VERSION "created by canmatrix"

NS_ :

BS_:

BU_: ME_AWS_CANA
VAL_TABLE_ CurDivValid 0 "Invalid" 1 "Description for the value '0x1'" ;
VAL_TABLE_ Lane_Type 0 "Dashed" 1 "Solid" 2 "undecided" 3 "Road Edge" 4 "Double Lane" 5 "Bott's Dots" 6 "invalid" ;
VAL_TABLE_ Model_Degree 0 "Parabolic model" 1 "Linear model" 2 "3rd-degree model" ;
VAL_TABLE_ Quality 0 "Low quality" 1 "Low quality" 2 "High quality" 3 "High quality" ;
VAL_TABLE_ Ref_Point_1_Validity 0 "Invalid" 1 "Valid" ;
VAL_TABLE_ Ref_Point_2_Validity 0 "Invalid" 1 "Valid" ;
VAL_TABLE_ Validity 0 "Invalid" 1 "Valid" ;
VAL_TABLE_ View_Ragne_Availability 0 "Not Valid" 1 "Valid" ;

BO_ 3221225472 VECTOR__INDEPENDENT_SIG_MSG: 0 Vector__XXX
 SG_ Shield_Configuration : 0|8@1+ (1,0) [0|0] "" Vector__XXX
 SG_ reserved : 0|32@1- (1,0) [0|255] "" Vector__XXX
 SG_ reserved3 : 0|3@1- (1,0) [0|3] "" Vector__XXX
 SG_ reserved2 : 0|2@1- (1,0) [0|1] "" Vector__XXX
 SG_ reserved1 : 0|2@1- (1,0) [0|1] "" Vector__XXX
 SG_ HighBeam : 0|1@1- (1,0) [0|1] "" Vector__XXX
 SG_ LowBeam : 0|1@1- (1,0) [0|1] "" Vector__XXX
 SG_ wippers : 0|1@1- (1,0) [0|1] "" Vector__XXX
 SG_ right_blink : 0|1@1- (1,0) [0|1] "" Vector__XXX
 SG_ Left_blink : 0|1@1- (1,0) [0|1] "" Vector__XXX
 SG_ Brakes : 0|1@1- (1,0) [0|1] "" Vector__XXX
 SG_ LowBeam_availabled : 0|1@1- (1,0) [0|1] "" Vector__XXX
 SG_ HighBeam_availabled : 0|1@1- (1,0) [0|1] "" Vector__XXX
 SG_ Wipers_availabled : 0|1@1- (1,0) [0|1] "" Vector__XXX
 SG_ View_Range_Availability : 0|1@1+ (1,0) [0|0] "" Vector__XXX
 SG_ View_Range : 0|15@1+ (0.00390625,0) [0|127.99609375] "meter" Vector__XXX
 SG_ Heading_Angle : 0|16@1+ (0.0009765625,-31.9990234375) [-0.357|0.357] "radians" Vector__XXX
 SG_ Reserved_10 : 0|3@1+ (1,0) [0|0] "" Vector__XXX
 SG_ Protocol_Version : 0|8@1+ (1,0) [0|255] "" Vector__XXX
 SG_ Active_Version_Number_Section : 0|2@1+ (1,0) [0|3] "" Vector__XXX
 SG_ Application_Version : 0|8@1+ (1,0) [0|255] "" Vector__XXX
 SG_ reserved5 : 0|5@1- (1,0) [0|23] "" Vector__XXX
 SG_ reserved4 : 0|5@1- (1,0) [0|4] "" Vector__XXX
 SG_ reserved20 : 0|2@1- (1,0) [0|0] "" Vector__XXX
 SG_ reserved21 : 0|1@1- (1,0) [0|0] "" Vector__XXX
 SG_ reserved0 : 0|5@1- (1,0) [0|0] "" Vector__XXX
 SG_ reserved1 : 0|3@1- (1,0) [0|0] "" Vector__XXX
 SG_ TSR_enabbled : 0|1@1+ (1,0) [0|1] "" Vector__XXX
 SG_ Rainy_HW_enabled : 0|1@1+ (1,0) [0|1] "" Vector__XXX
 SG_ Rain_HW : 0|1@1+ (1,0) [0|1] "" Vector__XXX
 SG_ HW_repeatable_enabled : 0|1@1+ (1,0) [0|1] "" Vector__XXX
 SG_ Blinker_reminder_enabled : 0|1@1+ (1,0) [0|1] "" Vector__XXX
 SG_ RLDW_on : 0|1@1+ (1,0) [0|1] "" Vector__XXX
 SG_ LLDW_on : 0|1@1+ (1,0) [0|1] "" Vector__XXX
 SG_ Maintenance : 0|1@1+ (1,0) [0|1] "" Vector__XXX
 SG_ Error_code : 0|7@1+ (1,0) [0|127] "" Vector__XXX
 SG_ Error_Active : 0|1@1+ (1,0) [0|1] "" Vector__XXX
 SG_ FLA_Armed : 0|1@1+ (1,0) [0|1] "" Vector__XXX
 SG_ Hi_Low_BeamControl : 0|1@1+ (1,0) [0|1] "" Vector__XXX
 SG_ Zero_speed : 0|1@1+ (1,0) [0|1] "" Vector__XXX
 SG_ Sound_type : 0|3@1+ (1,0) [0|7] "" Vector__XXX

BO_ 1888 signal_car: 8 Vector__XXX
 SG_ speed : 16|8@1+ (1,0) [0|255] "km\h" Vector__XXX

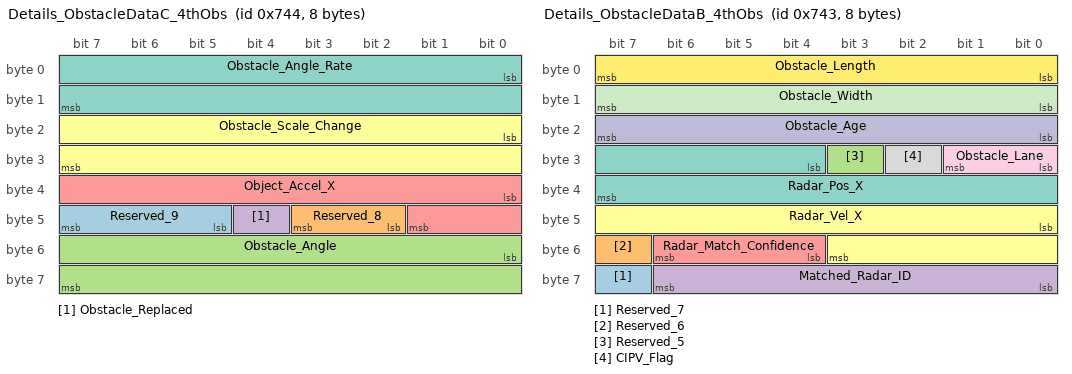
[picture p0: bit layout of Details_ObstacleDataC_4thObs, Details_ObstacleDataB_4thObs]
BO_ 1860 Details_ObstacleDataC_4thObs: 8 Vector__XXX
 SG_ Reserved_9 : 45|3@1+ (1,0) [0|0] "" Vector__XXX
 SG_ Reserved_8 : 42|2@1+ (1,0) [0|0] "" Vector__XXX
 SG_ Obstacle_Angle : 48|16@1- (0.01,0) [-327.68|327.67] "degree" Vector__XXX
 SG_ Obstacle_Replaced : 44|1@1+ (1,0) [0|0] "" Vector__XXX
 SG_ Object_Accel_X : 32|10@1- (0.03,0) [-15.36|15.33] "M/S2" Vector__XXX
 SG_ Obstacle_Scale_Change : 16|16@1- (0.0002,0) [-6.5536|6.5534] "pix/sec" Vector__XXX
 SG_ Obstacle_Angle_Rate : 0|16@1- (0.01,0) [-327.68|327.67] "degree" Vector__XXX

BO_ 1859 Details_ObstacleDataB_4thObs: 8 Vector__XXX
 SG_ Reserved_7 : 63|1@1+ (1,0) [0|0] "" Vector__XXX
 SG_ Reserved_6 : 55|1@1- (1,0) [0|0] "" Vector__XXX
 SG_ Reserved_5 : 27|1@1+ (1,0) [0|0] "" Vector__XXX
 SG_ Matched_Radar_ID : 56|7@1+ (1,0) [0|127] "" Vector__XXX
 SG_ Radar_Match_Confidence : 52|3@1+ (1,0) [0|7] "" Vector__XXX
 SG_ Radar_Vel_X : 40|12@1- (0.0625,0) [-128|127.9375] "meters/sec" Vector__XXX
 SG_ Radar_Pos_X : 28|12@1+ (0.0625,0) [0|255.9375] "meters" Vector__XXX
 SG_ CIPV_Flag : 26|1@1+ (1,0) [0|0] "" Vector__XXX
 SG_ Obstacle_Lane : 24|2@1+ (1,0) [0|3] "" Vector__XXX
 SG_ Obstacle_Age : 16|8@1+ (1,0) [0|255] "" Vector__XXX
 SG_ Obstacle_Width : 8|8@1+ (0.05,0) [0|12.75] "m" Vector__XXX
 SG_ Obstacle_Length : 0|8@1+ (0.5,0) [0|31] "m" Vector__XXX

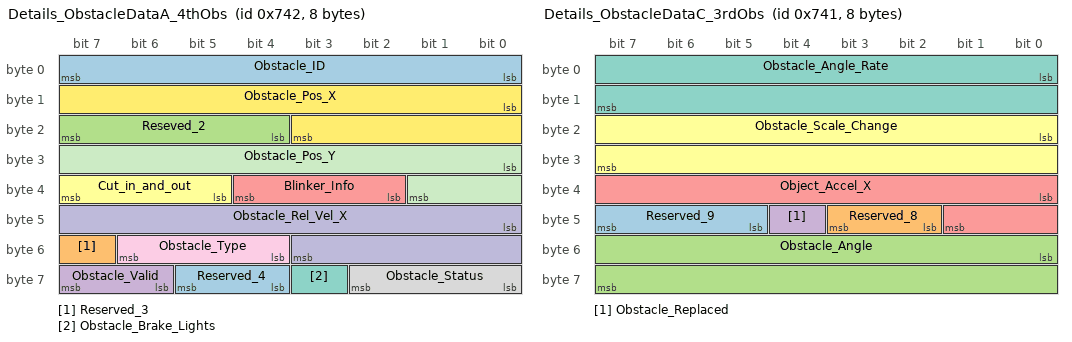
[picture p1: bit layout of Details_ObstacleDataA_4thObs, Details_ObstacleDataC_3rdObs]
BO_ 1858 Details_ObstacleDataA_4thObs: 8 Vector__XXX
 SG_ Reserved_4 : 60|2@1- (1,0) [0|0] "" Vector__XXX
 SG_ Reserved_3 : 55|1@1+ (1,0) [0|0] "" Vector__XXX
 SG_ Reseved_2 : 20|4@1+ (1,0) [0|0] "" Vector__XXX
 SG_ Obstacle_Valid : 62|2@1+ (1,0) [0|3] "" Vector__XXX
 SG_ Blinker_Info : 34|3@1+ (1,0) [0|7] "" Vector__XXX
 SG_ Cut_in_and_out : 37|3@1+ (1,0) [0|7] "" Vector__XXX
 SG_ Obstacle_Brake_Lights : 59|1@1- (1,0) [0|0] "" Vector__XXX
 SG_ Obstacle_Status : 56|3@1+ (1,0) [0|7] "" Vector__XXX
 SG_ Obstacle_Type : 52|3@1+ (1,0) [0|7] "" Vector__XXX
 SG_ Obstacle_Rel_Vel_X : 40|12@1- (0.0625,0) [-128|127.9375] "meters/sec" Vector__XXX
 SG_ Obstacle_Pos_Y : 24|10@1- (0.0625,0) [-32|31.9375] "meters" Vector__XXX
 SG_ Obstacle_Pos_X : 8|12@1+ (0.0625,0) [0|255.9375] "meters" Vector__XXX
 SG_ Obstacle_ID : 0|8@1+ (1,0) [0|63] "" Vector__XXX

BO_ 1857 Details_ObstacleDataC_3rdObs: 8 Vector__XXX
 SG_ Reserved_9 : 45|3@1+ (1,0) [0|0] "" Vector__XXX
 SG_ Reserved_8 : 42|2@1+ (1,0) [0|0] "" Vector__XXX
 SG_ Obstacle_Angle : 48|16@1- (0.01,0) [-327.68|327.67] "degree" Vector__XXX
 SG_ Obstacle_Replaced : 44|1@1+ (1,0) [0|0] "" Vector__XXX
 SG_ Object_Accel_X : 32|10@1- (0.03,0) [-15.36|15.33] "M/S2" Vector__XXX
 SG_ Obstacle_Scale_Change : 16|16@1- (0.0002,0) [-6.5536|6.5534] "pix/sec" Vector__XXX
 SG_ Obstacle_Angle_Rate : 0|16@1- (0.01,0) [-327.68|327.67] "degree" Vector__XXX

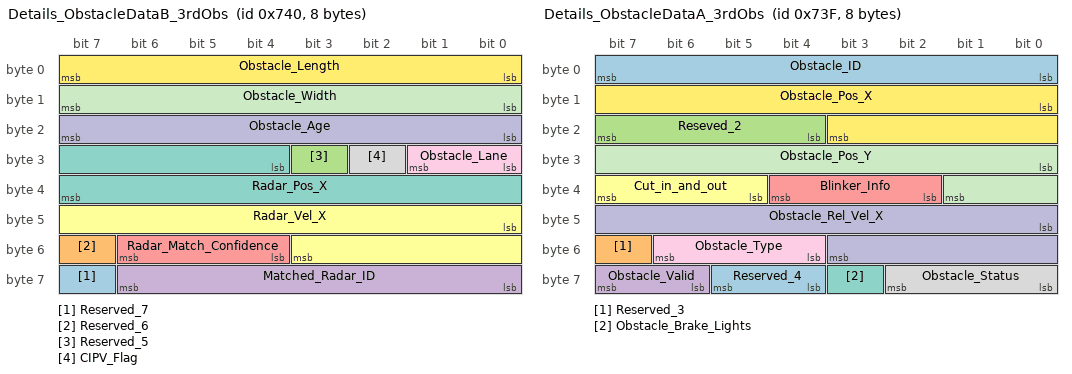
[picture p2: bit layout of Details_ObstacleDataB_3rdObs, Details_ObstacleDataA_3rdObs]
BO_ 1856 Details_ObstacleDataB_3rdObs: 8 Vector__XXX
 SG_ Reserved_7 : 63|1@1+ (1,0) [0|0] "" Vector__XXX
 SG_ Reserved_6 : 55|1@1- (1,0) [0|0] "" Vector__XXX
 SG_ Reserved_5 : 27|1@1+ (1,0) [0|0] "" Vector__XXX
 SG_ Matched_Radar_ID : 56|7@1+ (1,0) [0|127] "" Vector__XXX
 SG_ Radar_Match_Confidence : 52|3@1+ (1,0) [0|7] "" Vector__XXX
 SG_ Radar_Vel_X : 40|12@1- (0.0625,0) [-128|127.9375] "meters/sec" Vector__XXX
 SG_ Radar_Pos_X : 28|12@1+ (0.0625,0) [0|255.9375] "meters" Vector__XXX
 SG_ CIPV_Flag : 26|1@1+ (1,0) [0|0] "" Vector__XXX
 SG_ Obstacle_Lane : 24|2@1+ (1,0) [0|3] "" Vector__XXX
 SG_ Obstacle_Age : 16|8@1+ (1,0) [0|255] "" Vector__XXX
 SG_ Obstacle_Width : 8|8@1+ (0.05,0) [0|12.75] "m" Vector__XXX
 SG_ Obstacle_Length : 0|8@1+ (0.5,0) [0|31] "m" Vector__XXX

BO_ 1855 Details_ObstacleDataA_3rdObs: 8 Vector__XXX
 SG_ Reserved_4 : 60|2@1- (1,0) [0|0] "" Vector__XXX
 SG_ Reserved_3 : 55|1@1+ (1,0) [0|0] "" Vector__XXX
 SG_ Reseved_2 : 20|4@1+ (1,0) [0|0] "" Vector__XXX
 SG_ Obstacle_Valid : 62|2@1+ (1,0) [0|3] "" Vector__XXX
 SG_ Blinker_Info : 34|3@1+ (1,0) [0|7] "" Vector__XXX
 SG_ Cut_in_and_out : 37|3@1+ (1,0) [0|7] "" Vector__XXX
 SG_ Obstacle_Brake_Lights : 59|1@1- (1,0) [0|0] "" Vector__XXX
 SG_ Obstacle_Status : 56|3@1+ (1,0) [0|7] "" Vector__XXX
 SG_ Obstacle_Type : 52|3@1+ (1,0) [0|7] "" Vector__XXX
 SG_ Obstacle_Rel_Vel_X : 40|12@1- (0.0625,0) [-128|127.9375] "meters/sec" Vector__XXX
 SG_ Obstacle_Pos_Y : 24|10@1- (0.0625,0) [-32|31.9375] "meters" Vector__XXX
 SG_ Obstacle_Pos_X : 8|12@1+ (0.0625,0) [0|255.9375] "meters" Vector__XXX
 SG_ Obstacle_ID : 0|8@1+ (1,0) [0|63] "" Vector__XXX

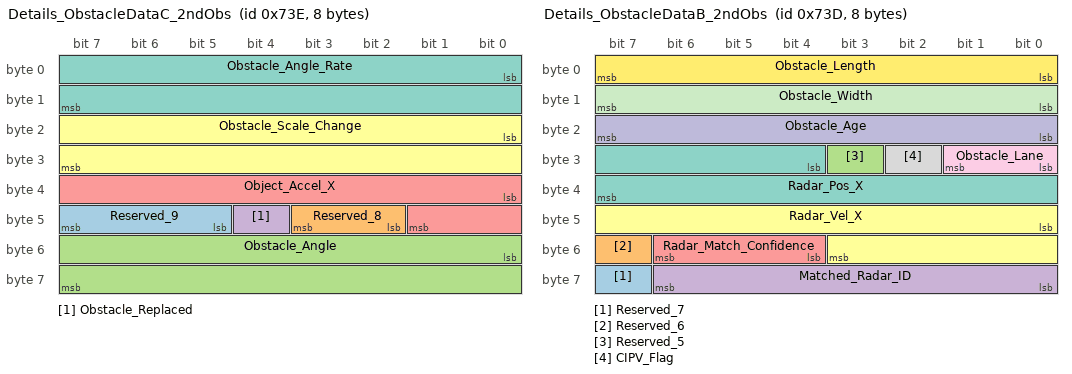
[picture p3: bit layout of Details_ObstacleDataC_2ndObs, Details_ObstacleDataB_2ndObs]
BO_ 1854 Details_ObstacleDataC_2ndObs: 8 Vector__XXX
 SG_ Reserved_9 : 45|3@1+ (1,0) [0|0] "" Vector__XXX
 SG_ Reserved_8 : 42|2@1+ (1,0) [0|0] "" Vector__XXX
 SG_ Obstacle_Angle : 48|16@1- (0.01,0) [-327.68|327.67] "degree" Vector__XXX
 SG_ Obstacle_Replaced : 44|1@1+ (1,0) [0|0] "" Vector__XXX
 SG_ Object_Accel_X : 32|10@1- (0.03,0) [-15.36|15.33] "M/S2" Vector__XXX
 SG_ Obstacle_Scale_Change : 16|16@1- (0.0002,0) [-6.5536|6.5534] "pix/sec" Vector__XXX
 SG_ Obstacle_Angle_Rate : 0|16@1- (0.01,0) [-327.68|327.67] "degree" Vector__XXX

BO_ 1853 Details_ObstacleDataB_2ndObs: 8 Vector__XXX
 SG_ Reserved_7 : 63|1@1+ (1,0) [0|0] "" Vector__XXX
 SG_ Reserved_6 : 55|1@1- (1,0) [0|0] "" Vector__XXX
 SG_ Reserved_5 : 27|1@1+ (1,0) [0|0] "" Vector__XXX
 SG_ Matched_Radar_ID : 56|7@1+ (1,0) [0|127] "" Vector__XXX
 SG_ Radar_Match_Confidence : 52|3@1+ (1,0) [0|7] "" Vector__XXX
 SG_ Radar_Vel_X : 40|12@1- (0.0625,0) [-128|127.9375] "meters/sec" Vector__XXX
 SG_ Radar_Pos_X : 28|12@1+ (0.0625,0) [0|255.9375] "meters" Vector__XXX
 SG_ CIPV_Flag : 26|1@1+ (1,0) [0|0] "" Vector__XXX
 SG_ Obstacle_Lane : 24|2@1+ (1,0) [0|3] "" Vector__XXX
 SG_ Obstacle_Age : 16|8@1+ (1,0) [0|255] "" Vector__XXX
 SG_ Obstacle_Width : 8|8@1+ (0.05,0) [0|12.75] "m" Vector__XXX
 SG_ Obstacle_Length : 0|8@1+ (0.5,0) [0|31] "m" Vector__XXX

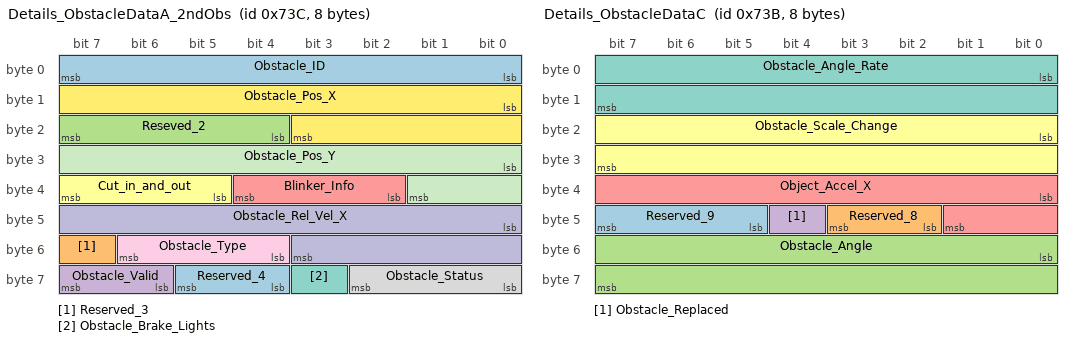
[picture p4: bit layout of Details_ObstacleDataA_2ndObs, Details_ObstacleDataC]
BO_ 1852 Details_ObstacleDataA_2ndObs: 8 Vector__XXX
 SG_ Reserved_4 : 60|2@1- (1,0) [0|0] "" Vector__XXX
 SG_ Reserved_3 : 55|1@1+ (1,0) [0|0] "" Vector__XXX
 SG_ Reseved_2 : 20|4@1+ (1,0) [0|0] "" Vector__XXX
 SG_ Obstacle_Valid : 62|2@1+ (1,0) [0|3] "" Vector__XXX
 SG_ Blinker_Info : 34|3@1+ (1,0) [0|7] "" Vector__XXX
 SG_ Cut_in_and_out : 37|3@1+ (1,0) [0|7] "" Vector__XXX
 SG_ Obstacle_Brake_Lights : 59|1@1- (1,0) [0|0] "" Vector__XXX
 SG_ Obstacle_Status : 56|3@1+ (1,0) [0|7] "" Vector__XXX
 SG_ Obstacle_Type : 52|3@1+ (1,0) [0|7] "" Vector__XXX
 SG_ Obstacle_Rel_Vel_X : 40|12@1- (0.0625,0) [-128|127.9375] "meters/sec" Vector__XXX
 SG_ Obstacle_Pos_Y : 24|10@1- (0.0625,0) [-32|31.9375] "meters" Vector__XXX
 SG_ Obstacle_Pos_X : 8|12@1+ (0.0625,0) [0|255.9375] "meters" Vector__XXX
 SG_ Obstacle_ID : 0|8@1+ (1,0) [0|63] "" Vector__XXX

BO_ 1851 Details_ObstacleDataC: 8 Vector__XXX
 SG_ Reserved_9 : 45|3@1+ (1,0) [0|0] "" Vector__XXX
 SG_ Reserved_8 : 42|2@1+ (1,0) [0|0] "" Vector__XXX
 SG_ Obstacle_Angle : 48|16@1- (0.01,0) [-327.68|327.67] "degree" Vector__XXX
 SG_ Obstacle_Replaced : 44|1@1+ (1,0) [0|0] "" Vector__XXX
 SG_ Object_Accel_X : 32|10@1- (0.03,0) [-15.36|15.33] "m/S2" Vector__XXX
 SG_ Obstacle_Scale_Change : 16|16@1- (0.0002,0) [-6.5536|6.5534] "pix/sec" Vector__XXX
 SG_ Obstacle_Angle_Rate : 0|16@1- (0.01,0) [-327.68|327.67] "degree" Vector__XXX

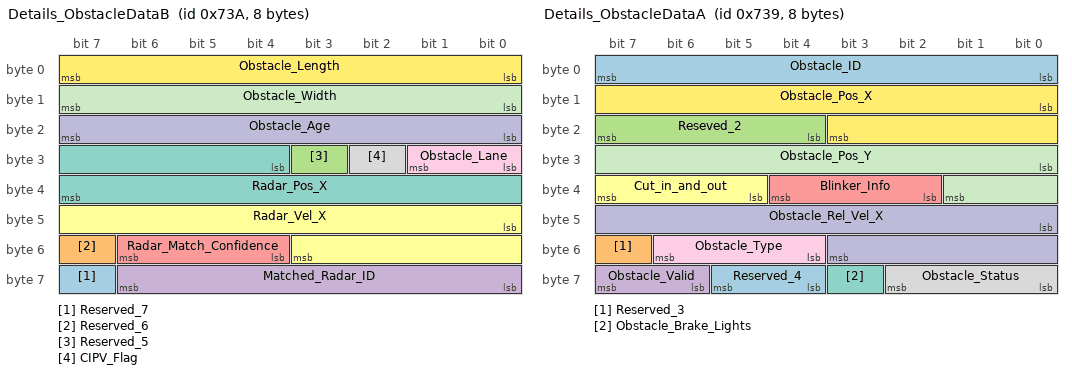
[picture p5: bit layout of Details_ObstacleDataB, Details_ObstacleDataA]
BO_ 1850 Details_ObstacleDataB: 8 Vector__XXX
 SG_ Reserved_7 : 63|1@1+ (1,0) [0|0] "" Vector__XXX
 SG_ Reserved_6 : 55|1@1- (1,0) [0|0] "" Vector__XXX
 SG_ Reserved_5 : 27|1@1+ (1,0) [0|0] "" Vector__XXX
 SG_ Matched_Radar_ID : 56|7@1+ (1,0) [0|127] "" Vector__XXX
 SG_ Radar_Match_Confidence : 52|3@1+ (1,0) [0|7] "" Vector__XXX
 SG_ Radar_Vel_X : 40|12@1- (0.0625,0) [-128|127.9375] "meters/sec" Vector__XXX
 SG_ Radar_Pos_X : 28|12@1+ (0.0625,0) [0|255.9375] "meters" Vector__XXX
 SG_ CIPV_Flag : 26|1@1+ (1,0) [0|0] "" Vector__XXX
 SG_ Obstacle_Lane : 24|2@1+ (1,0) [0|3] "" Vector__XXX
 SG_ Obstacle_Age : 16|8@1+ (1,0) [0|255] "" Vector__XXX
 SG_ Obstacle_Width : 8|8@1+ (0.05,0) [0|12.75] "meters" Vector__XXX
 SG_ Obstacle_Length : 0|8@1+ (0.5,0) [0|31] "meters" Vector__XXX

BO_ 1849 Details_ObstacleDataA: 8 Vector__XXX
 SG_ Reserved_4 : 60|2@1- (1,0) [0|0] "" Vector__XXX
 SG_ Reserved_3 : 55|1@1+ (1,0) [0|0] "" Vector__XXX
 SG_ Reseved_2 : 20|4@1+ (1,0) [0|0] "" Vector__XXX
 SG_ Obstacle_Valid : 62|2@1+ (1,0) [0|3] "" Vector__XXX
 SG_ Blinker_Info : 34|3@1+ (1,0) [0|7] "" Vector__XXX
 SG_ Cut_in_and_out : 37|3@1+ (1,0) [0|7] "" Vector__XXX
 SG_ Obstacle_Brake_Lights : 59|1@1- (1,0) [0|0] "" Vector__XXX
 SG_ Obstacle_Status : 56|3@1+ (1,0) [0|7] "" Vector__XXX
 SG_ Obstacle_Type : 52|3@1+ (1,0) [0|7] "" Vector__XXX
 SG_ Obstacle_Rel_Vel_X : 40|12@1- (0.0625,0) [-128|127.9375] "meters/sec" Vector__XXX
 SG_ Obstacle_Pos_Y : 24|10@1- (0.0625,0) [-32|31.9375] "meters" Vector__XXX
 SG_ Obstacle_Pos_X : 8|12@1+ (0.0625,0) [0|255.9375] "meters" Vector__XXX
 SG_ Obstacle_ID : 0|8@1+ (1,0) [0|63] "" Vector__XXX

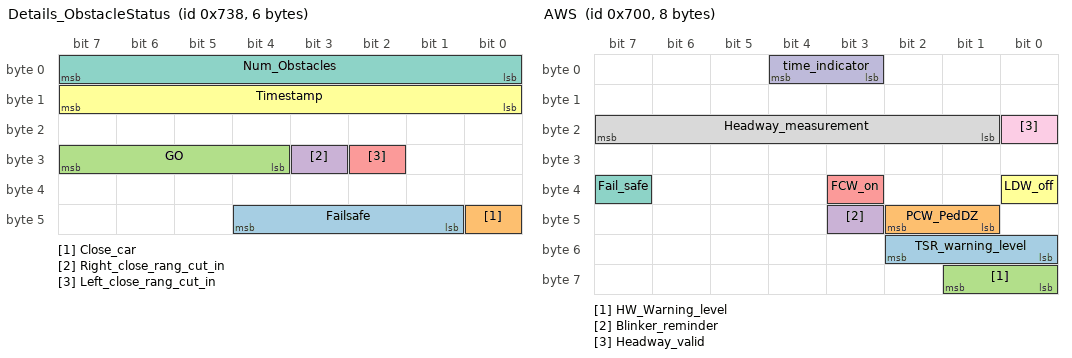
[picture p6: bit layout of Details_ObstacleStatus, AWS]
BO_ 1848 Details_ObstacleStatus: 6 Vector__XXX
 SG_ Failsafe : 41|4@1+ (1,0) [0|0] "" Vector__XXX
 SG_ Close_car : 40|1@1+ (1,0) [0|0] "" Vector__XXX
 SG_ GO : 28|4@1+ (1,0) [0|0] "" Vector__XXX
 SG_ Right_close_rang_cut_in : 27|1@1+ (1,0) [0|0] "" Vector__XXX
 SG_ Left_close_rang_cut_in : 26|1@1+ (1,0) [0|0] "" Vector__XXX
 SG_ Timestamp : 8|8@1+ (1,0) [0|255] "ms" Vector__XXX
 SG_ Num_Obstacles : 0|8@1+ (1,0) [0|255] "" Vector__XXX

BO_ 1792 AWS: 8 ME_AWS_CANA
 SG_ TSR_warning_level : 48|3@1+ (1,0) [0|3] "" Vector__XXX
 SG_ PCW_PedDZ : 41|2@1+ (1,0) [0|3] "" Vector__XXX
 SG_ HW_Warning_level : 56|2@1+ (1,0) [0|2] "" Vector__XXX
 SG_ Blinker_reminder : 43|1@1+ (1,0) [0|1] "" Vector__XXX
 SG_ FCW_on : 35|1@1+ (1,0) [0|1] "" Vector__XXX
 SG_ LDW_off : 32|1@1+ (1,0) [0|1] "" Vector__XXX
 SG_ Fail_safe : 39|1@1+ (1,0) [0|1] "" Vector__XXX
 SG_ Headway_measurement : 17|7@1+ (1,0) [0|127] "" Vector__XXX
 SG_ Headway_valid : 16|1@1+ (1,0) [0|1] "" Vector__XXX
 SG_ time_indicator : 3|2@1+ (1,0) [0|3] "" Vector__XXX

CM_ BO_ 3221225472 "This is a message for not used signals, created by Vector CANdb++ DBC OLE DB Provider.";
CM_ SG_ 3221225472 HighBeam "When signal is on the bit is on";
CM_ SG_ 3221225472 LowBeam "when signal is on the bit is on";
CM_ SG_ 3221225472 right_blink "When signal is on the bit is on";
CM_ SG_ 3221225472 Left_blink "When signal is on the bit is on";
CM_ SG_ 3221225472 Brakes "When signal is on the bit is on";
CM_ SG_ 3221225472 LowBeam_availabled "When signal availabled the bit is on";
CM_ SG_ 3221225472 HighBeam_availabled "When signal availabled the bit is on";
CM_ SG_ 3221225472 Wipers_availabled "When signal availabled the bit is on";
CM_ SG_ 3221225472 TSR_enabbled "When TSR feature is enabled the bit is on";
CM_ SG_ 3221225472 Rainy_HW_enabled "When the feature is active the bit is on";
CM_ SG_ 3221225472 Rain_HW "When rainy HW warning and rainy HW enabled the bit is on ";
CM_ SG_ 3221225472 HW_repeatable_enabled "When HW repeatable feature is active the bit is on";
CM_ SG_ 3221225472 Blinker_reminder_enabled "When the feature is active the bit is on";
CM_ SG_ 3221225472 RLDW_on "When Right LDW the bit is on during the warning";
CM_ SG_ 3221225472 LLDW_on "When left LDW the bit is on during the warning";
CM_ SG_ 3221225472 Maintenance "Indicator of internal error
1=error
0=no error";
CM_ SG_ 3221225472 Error_Active "When error active bit is off";
CM_ SG_ 3221225472 FLA_Armed "On :FLA armed and ready to work
";
CM_ SG_ 3221225472 Hi_Low_BeamControl "ON : FLA is armed and decision Highbeam is on";
CM_ SG_ 3221225472 Sound_type "0                Silent
1                LDWL
2                LDWR
3                HW
4                TSR warning (level 1,2,3)
5                Soft FCW
6                Hard FCW + Peds FCW
7                 Pedestrian in DZ";
CM_ BO_ 1860 "First Obstacle";
CM_ SG_ 1860 Obstacle_Replaced "Bool";
CM_ SG_ 1860 Object_Accel_X "Invalid value: 200h";
CM_ SG_ 1860 Obstacle_Scale_Change "Invalid value: 7FFh";
CM_ BO_ 1859 "First Obstacle";
CM_ SG_ 1859 Matched_Radar_ID "Invalid value: 7fh";
CM_ SG_ 1859 Radar_Match_Confidence "Invalid value: 0h";
CM_ SG_ 1859 Radar_Vel_X "Invalid value: 800h (also in case on no radar target matched)";
CM_ SG_ 1859 Obstacle_Width "Invalid value: FFh";
CM_ SG_ 1859 Obstacle_Length "Invalid value: 3Fh";
CM_ BO_ 1858 "First Obstacle";
CM_ SG_ 1858 Obstacle_Rel_Vel_X "Invalid value: 800h";
CM_ SG_ 1858 Obstacle_Pos_Y "Invalid value: 200h";
CM_ SG_ 1858 Obstacle_Pos_X "Invalid value: FFFh";
CM_ BO_ 1857 "First Obstacle";
CM_ SG_ 1857 Obstacle_Replaced "Bool";
CM_ SG_ 1857 Object_Accel_X "Invalid value: 200h";
CM_ SG_ 1857 Obstacle_Scale_Change "Invalid value: 7FFh";
CM_ BO_ 1856 "First Obstacle";
CM_ SG_ 1856 Matched_Radar_ID "Invalid value: 7fh";
CM_ SG_ 1856 Radar_Match_Confidence "Invalid value: 0h";
CM_ SG_ 1856 Radar_Vel_X "Invalid value: 800h (also in case on no radar target matched)";
CM_ SG_ 1856 Obstacle_Width "Invalid value: FFh";
CM_ SG_ 1856 Obstacle_Length "Invalid value: 3Fh";
CM_ BO_ 1855 "First Obstacle";
CM_ SG_ 1855 Obstacle_Rel_Vel_X "Invalid value: 800h";
CM_ SG_ 1855 Obstacle_Pos_Y "Invalid value: 200h";
CM_ SG_ 1855 Obstacle_Pos_X "Invalid value: FFFh";
CM_ BO_ 1854 "First Obstacle";
CM_ SG_ 1854 Obstacle_Replaced "Bool";
CM_ SG_ 1854 Object_Accel_X "Invalid value: 200h";
CM_ SG_ 1854 Obstacle_Scale_Change "Invalid value: 7FFh";
CM_ BO_ 1853 "First Obstacle";
CM_ SG_ 1853 Matched_Radar_ID "Invalid value: 7fh";
CM_ SG_ 1853 Radar_Match_Confidence "Invalid value: 0h";
CM_ SG_ 1853 Radar_Vel_X "Invalid value: 800h (also in case on no radar target matched)";
CM_ SG_ 1853 Obstacle_Width "Invalid value: FFh";
CM_ SG_ 1853 Obstacle_Length "Invalid value: 3Fh";
CM_ BO_ 1852 "First Obstacle";
CM_ SG_ 1852 Obstacle_Rel_Vel_X "Invalid value: 800h";
CM_ SG_ 1852 Obstacle_Pos_Y "Invalid value: 200h";
CM_ SG_ 1852 Obstacle_Pos_X "Invalid value: FFFh";
CM_ BO_ 1851 "First Obstacle";
CM_ SG_ 1851 Obstacle_Replaced "Bool";
CM_ SG_ 1851 Object_Accel_X "Invalid value: 200h";
CM_ SG_ 1851 Obstacle_Scale_Change "Invalid value: 7FFh";
CM_ BO_ 1850 "First Obstacle";
CM_ SG_ 1850 Matched_Radar_ID "Invalid value: 7fh";
CM_ SG_ 1850 Radar_Match_Confidence "Invalid value: 0h";
CM_ SG_ 1850 Radar_Vel_X "Invalid value: 800h (also in case on no radar target matched)";
CM_ SG_ 1850 Obstacle_Width "Invalid value: FFh";
CM_ SG_ 1850 Obstacle_Length "Invalid value: 3Fh";
CM_ BO_ 1849 "First Obstacle";
CM_ SG_ 1849 Obstacle_Rel_Vel_X "Invalid value: 800h";
CM_ SG_ 1849 Obstacle_Pos_Y "Invalid value: 200h";
CM_ SG_ 1849 Obstacle_Pos_X "Invalid value: FFFh";
CM_ SG_ 1848 Close_car "Bool";
CM_ SG_ 1792 HW_Warning_level "When HW configuration <= 0.6 and CIPV <= 0.6 headway warning level =2";
CM_ SG_ 1792 Blinker_reminder "When warning and feature is active the bit is on";
CM_ SG_ 1792 FCW_on "When FCW bit is on";
CM_ SG_ 1792 LDW_off "When low speed ,low confidence lanes or configuration off the bit is on";
CM_ SG_ 1792 Headway_measurement "If speed >=30 and Headway valid on
When HW measurment >2.5  then HW measurment =0";
CM_ SG_ 1792 Headway_valid "Speed >=30 and CIPV";
CM_ SG_ 1792 time_indicator "0     Day
1     Dusk
2     Night
3     not in use";
BA_DEF_  "BusType" STRING ;
BA_DEF_DEF_  "BusType" "CAN";
VAL_ 3221225472 Shield_Configuration 0 "Not availabled" ;
VAL_ 3221225472 HighBeam 0 "off" 1 "on" ;
VAL_ 3221225472 LowBeam 0 "off" 1 "on" ;
VAL_ 3221225472 wippers 0 "off" 1 "on" ;
VAL_ 3221225472 right_blink 0 "off" 1 "on" ;
VAL_ 3221225472 Left_blink 0 "off" 1 "on" ;
VAL_ 3221225472 Brakes 0 "off" 1 "on" ;
VAL_ 3221225472 LowBeam_availabled 0 "off" 1 "on" ;
VAL_ 3221225472 HighBeam_availabled 0 "off" 1 "on" ;
VAL_ 3221225472 Wipers_availabled 0 "off" 1 "on" ;
VAL_ 3221225472 View_Range_Availability 0 "Not Valid" 1 "Valid" ;
VAL_ 3221225472 TSR_enabbled 0 "OFF" 1 "ON" ;
VAL_ 3221225472 Rainy_HW_enabled 0 "OFF" 1 "ON" ;
VAL_ 3221225472 Rain_HW 0 "OFF" 1 "ON" ;
VAL_ 3221225472 HW_repeatable_enabled 0 "OFF" 1 "ON" ;
VAL_ 3221225472 Blinker_reminder_enabled 0 "OFF" 1 "ON" ;
VAL_ 3221225472 RLDW_on 0 "OFF" 1 "ON" ;
VAL_ 3221225472 LLDW_on 0 "OFF" 1 "ON" ;
VAL_ 3221225472 Maintenance 0 "OFF" 1 "ON" ;
VAL_ 3221225472 Error_code 10 "Er-10" 20 "Er-20" 21 "Er-21" 22 "Er-22" 30 "Er-30" 31 "Er-31" 32 "Er-32" 33 "Er-33" 34 "Er-34" 35 "Er-35" 40 "Er-40" 41 "Er-41" 50 "Er-50" 60 "Er-60" ;
VAL_ 3221225472 Error_Active 0 "OFF" 1 "ON" ;
VAL_ 3221225472 FLA_Armed 0 "OFF" 1 "ON" ;
VAL_ 3221225472 Hi_Low_BeamControl 0 "OFF" 1 "ON" ;
VAL_ 3221225472 Zero_speed 0 "OFF" 1 "ON" ;
VAL_ 3221225472 Sound_type 0 "No sound" 1 "Left LDW" 2 "Right LDW" 3 "HW" 4 "TSR Warning" 5 "Soft FCW \Virtual bumper" 6 "FCW\PCW" 7 "Pedestrian in DZ" ;
VAL_ 1860 Obstacle_Replaced 0 "Not replaced in this frame" 1 "Replace in this frame" ;
VAL_ 1859 Radar_Match_Confidence 0 "No match" 1 "Multi match" 2 "vision  - radar match" 3 "vision  - radar match" 4 "vision  - radar match" 5 "high confidence match" ;
VAL_ 1859 CIPV_Flag 0 "Not CIPV" 1 "CIPV" ;
VAL_ 1859 Obstacle_Lane 0 "Not assigned" 1 "Ego lane" 2 "Next lane " 3 "Invalid signal" ;
VAL_ 1859 Obstacle_Length 0 "0.0" 1 "0.5" 2 "1.0" 3 "1.5" 4 "2.0" 5 "2.5" 6 "3.0" 7 "3.5" 8 "4.0" 9 "4.5" 10 "5.0" 11 "5.5" 12 "6.0" 13 "6.5" 14 "7.0" 15 "7.5" 16 "8.0" 17 "8.5" 18 "9.0" 19 "9.5" 20 "10.0" 21 "10.5" 22 "11.0" 23 "11.5" 24 "12.0" 25 "12.5" 26 "13.0" 27 "13.5" 28 "14.0" 29 "14.5" 30 "15.0" 31 "15.5" 32 "16.0" 33 "16.5" 34 "17.0" 35 "17.5" 36 "18.0" 37 "18.5" 38 "19.0" 39 "19.5" 40 "20.0" 41 "20.5" 42 "21.0" 43 "21.5" 44 "22.0" 45 "22.5" 46 "23.0" 47 "23.5" 48 "24.0" 49 "24.5" 50 "25.0" 51 "25.5" 52 "26.0" 53 "26.5" 54 "27.0" 55 "27.5" 56 "28.0" 57 "28.5" 58 "29.0" 59 "29.5" 60 "30.0" 61 "30.5" 62 "31.0" 63 "Invalid Value" 64 "Invalid Value" 65 "Invalid Value" 66 "Invalid Value" 67 "Invalid Value" 68 "Invalid Value" 69 "Invalid Value" 70 "Invalid Value" 71 "Invalid Value" 72 "Invalid Value" 73 "Invalid Value" 74 "Invalid Value" 75 "Invalid Value" 76 "Invalid Value" 77 "Invalid Value" 78 "Invalid Value" 79 "Invalid Value" 80 "Invalid Value" 81 "Invalid Value" 82 "Invalid Value" 83 "Invalid Value" 84 "Invalid Value" 85 "Invalid Value" 86 "Invalid Value" 87 "Invalid Value" 88 "Invalid Value" 89 "Invalid Value" 90 "Invalid Value" 91 "Invalid Value" 92 "Invalid Value" 93 "Invalid Value" 94 "Invalid Value" 95 "Invalid Value" 96 "Invalid Value" 97 "Invalid Value" 98 "Invalid Value" 99 "Invalid Value" 100 "Invalid Value" 101 "Invalid Value" 102 "Invalid Value" 103 "Invalid Value" 104 "Invalid Value" 105 "Invalid Value" 106 "Invalid Value" 107 "Invalid Value" 108 "Invalid Value" 109 "Invalid Value" 110 "Invalid Value" 111 "Invalid Value" 112 "Invalid Value" 113 "Invalid Value" 114 "Invalid Value" 115 "Invalid Value" 116 "Invalid Value" 117 "Invalid Value" 118 "Invalid Value" 119 "Invalid Value" 120 "Invalid Value" 121 "Invalid Value" 122 "Invalid Value" 123 "Invalid Value" 124 "Invalid Value" 125 "Invalid Value" 126 "Invalid Value" 127 "Invalid Value" 128 "Invalid Value" 129 "Invalid Value" 130 "Invalid Value" 131 "Invalid Value" 132 "Invalid Value" 133 "Invalid Value" 134 "Invalid Value" 135 "Invalid Value" 136 "Invalid Value" 137 "Invalid Value" 138 "Invalid Value" 139 "Invalid Value" 140 "Invalid Value" 141 "Invalid Value" 142 "Invalid Value" 143 "Invalid Value" 144 "Invalid Value" 145 "Invalid Value" 146 "Invalid Value" 147 "Invalid Value" 148 "Invalid Value" 149 "Invalid Value" 150 "Invalid Value" 151 "Invalid Value" 152 "Invalid Value" 153 "Invalid Value" 154 "Invalid Value" 155 "Invalid Value" 156 "Invalid Value" 157 "Invalid Value" 158 "Invalid Value" 159 "Invalid Value" 160 "Invalid Value" 161 "Invalid Value" 162 "Invalid Value" 163 "Invalid Value" 164 "Invalid Value" 165 "Invalid Value" 166 "Invalid Value" 167 "Invalid Value" 168 "Invalid Value" 169 "Invalid Value" 170 "Invalid Value" 171 "Invalid Value" 172 "Invalid Value" 173 "Invalid Value" 174 "Invalid Value" 175 "Invalid Value" 176 "Invalid Value" 177 "Invalid Value" 178 "Invalid Value" 179 "Invalid Value" 180 "Invalid Value" 181 "Invalid Value" 182 "Invalid Value" 183 "Invalid Value" 184 "Invalid Value" 185 "Invalid Value" 186 "Invalid Value" 187 "Invalid Value" 188 "Invalid Value" 189 "Invalid Value" 190 "Invalid Value" 191 "Invalid Value" 192 "Invalid Value" 193 "Invalid Value" 194 "Invalid Value" 195 "Invalid Value" 196 "Invalid Value" 197 "Invalid Value" 198 "Invalid Value" 199 "Invalid Value" 200 "Invalid Value" 201 "Invalid Value" 202 "Invalid Value" 203 "Invalid Value" 204 "Invalid Value" 205 "Invalid Value" 206 "Invalid Value" 207 "Invalid Value" 208 "Invalid Value" 209 "Invalid Value" 210 "Invalid Value" 211 "Invalid Value" 212 "Invalid Value" 213 "Invalid Value" 214 "Invalid Value" 215 "Invalid Value" 216 "Invalid Value" 217 "Invalid Value" 218 "Invalid Value" 219 "Invalid Value" 220 "Invalid Value" 221 "Invalid Value" 222 "Invalid Value" 223 "Invalid Value" 224 "Invalid Value" 225 "Invalid Value" 226 "Invalid Value" 227 "Invalid Value" 228 "Invalid Value" 229 "Invalid Value" 230 "Invalid Value" 231 "Invalid Value" 232 "Invalid Value" 233 "Invalid Value" 234 "Invalid Value" 235 "Invalid Value" 236 "Invalid Value" 237 "Invalid Value" 238 "Invalid Value" 239 "Invalid Value" 240 "Invalid Value" 241 "Invalid Value" 242 "Invalid Value" 243 "Invalid Value" 244 "Invalid Value" 245 "Invalid Value" 246 "Invalid Value" 247 "Invalid Value" 248 "Invalid Value" 249 "Invalid Value" 250 "Invalid Value" 251 "Invalid Value" 252 "Invalid Value" 253 "Invalid Value" 254 "Invalid Value" 255 "Invalid Value" ;
VAL_ 1858 Obstacle_Valid 1 "New valid " 2 "Older valid" ;
VAL_ 1858 Blinker_Info 0 "unavailable" 1 "Off" 2 "Left" 3 "Right" 4 "Both" ;
VAL_ 1858 Cut_in_and_out 0 "undefined " 1 "in_host_lane " 2 "out_host_lane " 3 "cut_in " 4 "cut_out " ;
VAL_ 1858 Obstacle_Brake_Lights 0 "object's brake lights are off" 1 "object's brake lights are on" ;
VAL_ 1858 Obstacle_Status 0 "Unused" 1 "Standing" 2 "Stopped " 3 "Moving" 4 "Oncoming" 5 "Parked " 6 "Unused" ;
VAL_ 1858 Obstacle_Type 0 "Vehicle" 1 "Truck" 2 "Bike" 3 "Ped" 4 "Bicycle" 5 "Unused" 6 "Unused" 7 "Unused" ;
VAL_ 1857 Obstacle_Replaced 0 "Not replaced in this frame" 1 "Replace in this frame" ;
VAL_ 1856 Radar_Match_Confidence 0 "No match" 1 "Multi match" 2 "vision  - radar match" 3 "vision  - radar match" 4 "vision  - radar match" 5 "high confidence match" ;
VAL_ 1856 CIPV_Flag 0 "Not CIPV" 1 "CIPV" ;
VAL_ 1856 Obstacle_Lane 0 "Not assigned" 1 "Ego lane" 2 "Next lane " 3 "Invalid signal" ;
VAL_ 1856 Obstacle_Length 0 "0.0" 1 "0.5" 2 "1.0" 3 "1.5" 4 "2.0" 5 "2.5" 6 "3.0" 7 "3.5" 8 "4.0" 9 "4.5" 10 "5.0" 11 "5.5" 12 "6.0" 13 "6.5" 14 "7.0" 15 "7.5" 16 "8.0" 17 "8.5" 18 "9.0" 19 "9.5" 20 "10.0" 21 "10.5" 22 "11.0" 23 "11.5" 24 "12.0" 25 "12.5" 26 "13.0" 27 "13.5" 28 "14.0" 29 "14.5" 30 "15.0" 31 "15.5" 32 "16.0" 33 "16.5" 34 "17.0" 35 "17.5" 36 "18.0" 37 "18.5" 38 "19.0" 39 "19.5" 40 "20.0" 41 "20.5" 42 "21.0" 43 "21.5" 44 "22.0" 45 "22.5" 46 "23.0" 47 "23.5" 48 "24.0" 49 "24.5" 50 "25.0" 51 "25.5" 52 "26.0" 53 "26.5" 54 "27.0" 55 "27.5" 56 "28.0" 57 "28.5" 58 "29.0" 59 "29.5" 60 "30.0" 61 "30.5" 62 "31.0" 63 "Invalid Value" 64 "Invalid Value" 65 "Invalid Value" 66 "Invalid Value" 67 "Invalid Value" 68 "Invalid Value" 69 "Invalid Value" 70 "Invalid Value" 71 "Invalid Value" 72 "Invalid Value" 73 "Invalid Value" 74 "Invalid Value" 75 "Invalid Value" 76 "Invalid Value" 77 "Invalid Value" 78 "Invalid Value" 79 "Invalid Value" 80 "Invalid Value" 81 "Invalid Value" 82 "Invalid Value" 83 "Invalid Value" 84 "Invalid Value" 85 "Invalid Value" 86 "Invalid Value" 87 "Invalid Value" 88 "Invalid Value" 89 "Invalid Value" 90 "Invalid Value" 91 "Invalid Value" 92 "Invalid Value" 93 "Invalid Value" 94 "Invalid Value" 95 "Invalid Value" 96 "Invalid Value" 97 "Invalid Value" 98 "Invalid Value" 99 "Invalid Value" 100 "Invalid Value" 101 "Invalid Value" 102 "Invalid Value" 103 "Invalid Value" 104 "Invalid Value" 105 "Invalid Value" 106 "Invalid Value" 107 "Invalid Value" 108 "Invalid Value" 109 "Invalid Value" 110 "Invalid Value" 111 "Invalid Value" 112 "Invalid Value" 113 "Invalid Value" 114 "Invalid Value" 115 "Invalid Value" 116 "Invalid Value" 117 "Invalid Value" 118 "Invalid Value" 119 "Invalid Value" 120 "Invalid Value" 121 "Invalid Value" 122 "Invalid Value" 123 "Invalid Value" 124 "Invalid Value" 125 "Invalid Value" 126 "Invalid Value" 127 "Invalid Value" 128 "Invalid Value" 129 "Invalid Value" 130 "Invalid Value" 131 "Invalid Value" 132 "Invalid Value" 133 "Invalid Value" 134 "Invalid Value" 135 "Invalid Value" 136 "Invalid Value" 137 "Invalid Value" 138 "Invalid Value" 139 "Invalid Value" 140 "Invalid Value" 141 "Invalid Value" 142 "Invalid Value" 143 "Invalid Value" 144 "Invalid Value" 145 "Invalid Value" 146 "Invalid Value" 147 "Invalid Value" 148 "Invalid Value" 149 "Invalid Value" 150 "Invalid Value" 151 "Invalid Value" 152 "Invalid Value" 153 "Invalid Value" 154 "Invalid Value" 155 "Invalid Value" 156 "Invalid Value" 157 "Invalid Value" 158 "Invalid Value" 159 "Invalid Value" 160 "Invalid Value" 161 "Invalid Value" 162 "Invalid Value" 163 "Invalid Value" 164 "Invalid Value" 165 "Invalid Value" 166 "Invalid Value" 167 "Invalid Value" 168 "Invalid Value" 169 "Invalid Value" 170 "Invalid Value" 171 "Invalid Value" 172 "Invalid Value" 173 "Invalid Value" 174 "Invalid Value" 175 "Invalid Value" 176 "Invalid Value" 177 "Invalid Value" 178 "Invalid Value" 179 "Invalid Value" 180 "Invalid Value" 181 "Invalid Value" 182 "Invalid Value" 183 "Invalid Value" 184 "Invalid Value" 185 "Invalid Value" 186 "Invalid Value" 187 "Invalid Value" 188 "Invalid Value" 189 "Invalid Value" 190 "Invalid Value" 191 "Invalid Value" 192 "Invalid Value" 193 "Invalid Value" 194 "Invalid Value" 195 "Invalid Value" 196 "Invalid Value" 197 "Invalid Value" 198 "Invalid Value" 199 "Invalid Value" 200 "Invalid Value" 201 "Invalid Value" 202 "Invalid Value" 203 "Invalid Value" 204 "Invalid Value" 205 "Invalid Value" 206 "Invalid Value" 207 "Invalid Value" 208 "Invalid Value" 209 "Invalid Value" 210 "Invalid Value" 211 "Invalid Value" 212 "Invalid Value" 213 "Invalid Value" 214 "Invalid Value" 215 "Invalid Value" 216 "Invalid Value" 217 "Invalid Value" 218 "Invalid Value" 219 "Invalid Value" 220 "Invalid Value" 221 "Invalid Value" 222 "Invalid Value" 223 "Invalid Value" 224 "Invalid Value" 225 "Invalid Value" 226 "Invalid Value" 227 "Invalid Value" 228 "Invalid Value" 229 "Invalid Value" 230 "Invalid Value" 231 "Invalid Value" 232 "Invalid Value" 233 "Invalid Value" 234 "Invalid Value" 235 "Invalid Value" 236 "Invalid Value" 237 "Invalid Value" 238 "Invalid Value" 239 "Invalid Value" 240 "Invalid Value" 241 "Invalid Value" 242 "Invalid Value" 243 "Invalid Value" 244 "Invalid Value" 245 "Invalid Value" 246 "Invalid Value" 247 "Invalid Value" 248 "Invalid Value" 249 "Invalid Value" 250 "Invalid Value" 251 "Invalid Value" 252 "Invalid Value" 253 "Invalid Value" 254 "Invalid Value" 255 "Invalid Value" ;
VAL_ 1855 Obstacle_Valid 1 "New valid " 2 "Older valid" ;
VAL_ 1855 Blinker_Info 0 "unavailable" 1 "Off" 2 "Left" 3 "Right" 4 "Both" ;
VAL_ 1855 Cut_in_and_out 0 "undefined " 1 "in_host_lane " 2 "out_host_lane " 3 "cut_in " 4 "cut_out " ;
VAL_ 1855 Obstacle_Brake_Lights 0 "object's brake lights are off" 1 "object's brake lights are on" ;
VAL_ 1855 Obstacle_Status 0 "Unused" 1 "Standing" 2 "Stopped " 3 "Moving" 4 "Oncoming" 5 "Parked " 6 "Unused" ;
VAL_ 1855 Obstacle_Type 0 "Vehicle" 1 "Truck" 2 "Bike" 3 "Ped" 4 "Bicycle" 5 "Unused" 6 "Unused" 7 "Unused" ;
VAL_ 1854 Obstacle_Replaced 0 "Not replaced in this frame" 1 "Replace in this frame" ;
VAL_ 1853 Radar_Match_Confidence 0 "No match" 1 "Multi match" 2 "vision  - radar match" 3 "vision  - radar match" 4 "vision  - radar match" 5 "high confidence match" ;
VAL_ 1853 CIPV_Flag 0 "Not CIPV" 1 "CIPV" ;
VAL_ 1853 Obstacle_Lane 0 "Not assigned" 1 "Ego lane" 2 "Next lane " 3 "Invalid signal" ;
VAL_ 1853 Obstacle_Length 0 "0.0" 1 "0.5" 2 "1.0" 3 "1.5" 4 "2.0" 5 "2.5" 6 "3.0" 7 "3.5" 8 "4.0" 9 "4.5" 10 "5.0" 11 "5.5" 12 "6.0" 13 "6.5" 14 "7.0" 15 "7.5" 16 "8.0" 17 "8.5" 18 "9.0" 19 "9.5" 20 "10.0" 21 "10.5" 22 "11.0" 23 "11.5" 24 "12.0" 25 "12.5" 26 "13.0" 27 "13.5" 28 "14.0" 29 "14.5" 30 "15.0" 31 "15.5" 32 "16.0" 33 "16.5" 34 "17.0" 35 "17.5" 36 "18.0" 37 "18.5" 38 "19.0" 39 "19.5" 40 "20.0" 41 "20.5" 42 "21.0" 43 "21.5" 44 "22.0" 45 "22.5" 46 "23.0" 47 "23.5" 48 "24.0" 49 "24.5" 50 "25.0" 51 "25.5" 52 "26.0" 53 "26.5" 54 "27.0" 55 "27.5" 56 "28.0" 57 "28.5" 58 "29.0" 59 "29.5" 60 "30.0" 61 "30.5" 62 "31.0" 63 "Invalid Value" 64 "Invalid Value" 65 "Invalid Value" 66 "Invalid Value" 67 "Invalid Value" 68 "Invalid Value" 69 "Invalid Value" 70 "Invalid Value" 71 "Invalid Value" 72 "Invalid Value" 73 "Invalid Value" 74 "Invalid Value" 75 "Invalid Value" 76 "Invalid Value" 77 "Invalid Value" 78 "Invalid Value" 79 "Invalid Value" 80 "Invalid Value" 81 "Invalid Value" 82 "Invalid Value" 83 "Invalid Value" 84 "Invalid Value" 85 "Invalid Value" 86 "Invalid Value" 87 "Invalid Value" 88 "Invalid Value" 89 "Invalid Value" 90 "Invalid Value" 91 "Invalid Value" 92 "Invalid Value" 93 "Invalid Value" 94 "Invalid Value" 95 "Invalid Value" 96 "Invalid Value" 97 "Invalid Value" 98 "Invalid Value" 99 "Invalid Value" 100 "Invalid Value" 101 "Invalid Value" 102 "Invalid Value" 103 "Invalid Value" 104 "Invalid Value" 105 "Invalid Value" 106 "Invalid Value" 107 "Invalid Value" 108 "Invalid Value" 109 "Invalid Value" 110 "Invalid Value" 111 "Invalid Value" 112 "Invalid Value" 113 "Invalid Value" 114 "Invalid Value" 115 "Invalid Value" 116 "Invalid Value" 117 "Invalid Value" 118 "Invalid Value" 119 "Invalid Value" 120 "Invalid Value" 121 "Invalid Value" 122 "Invalid Value" 123 "Invalid Value" 124 "Invalid Value" 125 "Invalid Value" 126 "Invalid Value" 127 "Invalid Value" 128 "Invalid Value" 129 "Invalid Value" 130 "Invalid Value" 131 "Invalid Value" 132 "Invalid Value" 133 "Invalid Value" 134 "Invalid Value" 135 "Invalid Value" 136 "Invalid Value" 137 "Invalid Value" 138 "Invalid Value" 139 "Invalid Value" 140 "Invalid Value" 141 "Invalid Value" 142 "Invalid Value" 143 "Invalid Value" 144 "Invalid Value" 145 "Invalid Value" 146 "Invalid Value" 147 "Invalid Value" 148 "Invalid Value" 149 "Invalid Value" 150 "Invalid Value" 151 "Invalid Value" 152 "Invalid Value" 153 "Invalid Value" 154 "Invalid Value" 155 "Invalid Value" 156 "Invalid Value" 157 "Invalid Value" 158 "Invalid Value" 159 "Invalid Value" 160 "Invalid Value" 161 "Invalid Value" 162 "Invalid Value" 163 "Invalid Value" 164 "Invalid Value" 165 "Invalid Value" 166 "Invalid Value" 167 "Invalid Value" 168 "Invalid Value" 169 "Invalid Value" 170 "Invalid Value" 171 "Invalid Value" 172 "Invalid Value" 173 "Invalid Value" 174 "Invalid Value" 175 "Invalid Value" 176 "Invalid Value" 177 "Invalid Value" 178 "Invalid Value" 179 "Invalid Value" 180 "Invalid Value" 181 "Invalid Value" 182 "Invalid Value" 183 "Invalid Value" 184 "Invalid Value" 185 "Invalid Value" 186 "Invalid Value" 187 "Invalid Value" 188 "Invalid Value" 189 "Invalid Value" 190 "Invalid Value" 191 "Invalid Value" 192 "Invalid Value" 193 "Invalid Value" 194 "Invalid Value" 195 "Invalid Value" 196 "Invalid Value" 197 "Invalid Value" 198 "Invalid Value" 199 "Invalid Value" 200 "Invalid Value" 201 "Invalid Value" 202 "Invalid Value" 203 "Invalid Value" 204 "Invalid Value" 205 "Invalid Value" 206 "Invalid Value" 207 "Invalid Value" 208 "Invalid Value" 209 "Invalid Value" 210 "Invalid Value" 211 "Invalid Value" 212 "Invalid Value" 213 "Invalid Value" 214 "Invalid Value" 215 "Invalid Value" 216 "Invalid Value" 217 "Invalid Value" 218 "Invalid Value" 219 "Invalid Value" 220 "Invalid Value" 221 "Invalid Value" 222 "Invalid Value" 223 "Invalid Value" 224 "Invalid Value" 225 "Invalid Value" 226 "Invalid Value" 227 "Invalid Value" 228 "Invalid Value" 229 "Invalid Value" 230 "Invalid Value" 231 "Invalid Value" 232 "Invalid Value" 233 "Invalid Value" 234 "Invalid Value" 235 "Invalid Value" 236 "Invalid Value" 237 "Invalid Value" 238 "Invalid Value" 239 "Invalid Value" 240 "Invalid Value" 241 "Invalid Value" 242 "Invalid Value" 243 "Invalid Value" 244 "Invalid Value" 245 "Invalid Value" 246 "Invalid Value" 247 "Invalid Value" 248 "Invalid Value" 249 "Invalid Value" 250 "Invalid Value" 251 "Invalid Value" 252 "Invalid Value" 253 "Invalid Value" 254 "Invalid Value" 255 "Invalid Value" ;
VAL_ 1852 Obstacle_Valid 1 "New valid " 2 "Older valid" ;
VAL_ 1852 Blinker_Info 0 "unavailable" 1 "Off" 2 "Left" 3 "Right" 4 "Both" ;
VAL_ 1852 Cut_in_and_out 0 "undefined " 1 "in_host_lane " 2 "out_host_lane " 3 "cut_in " 4 "cut_out " ;
VAL_ 1852 Obstacle_Brake_Lights 0 "object's brake lights are off" 1 "object's brake lights are on" ;
VAL_ 1852 Obstacle_Status 0 "Unused" 1 "Standing" 2 "Stopped " 3 "Moving" 4 "Oncoming" 5 "Parked " 6 "Unused" ;
VAL_ 1852 Obstacle_Type 0 "Vehicle" 1 "Truck" 2 "Bike" 3 "Ped" 4 "Bicycle" 5 "Unused" 6 "Unused" 7 "Unused" ;
VAL_ 1851 Obstacle_Replaced 0 "Not replaced in this frame" 1 "Replace in this frame" ;
VAL_ 1850 Radar_Match_Confidence 0 "No match" 1 "Multi match" 2 "vision  - radar match" 3 "vision  - radar match" 4 "vision  - radar match" 5 "high confidence match" ;
VAL_ 1850 CIPV_Flag 0 "Not CIPV" 1 "CIPV" ;
VAL_ 1850 Obstacle_Lane 0 "Not assigned" 1 "Ego lane" 2 "Next lane " 3 "Invalid signal" ;
VAL_ 1850 Obstacle_Length 0 "0.0" 1 "0.5" 2 "1.0" 3 "1.5" 4 "2.0" 5 "2.5" 6 "3.0" 7 "3.5" 8 "4.0" 9 "4.5" 10 "5.0" 11 "5.5" 12 "6.0" 13 "6.5" 14 "7.0" 15 "7.5" 16 "8.0" 17 "8.5" 18 "9.0" 19 "9.5" 20 "10.0" 21 "10.5" 22 "11.0" 23 "11.5" 24 "12.0" 25 "12.5" 26 "13.0" 27 "13.5" 28 "14.0" 29 "14.5" 30 "15.0" 31 "15.5" 32 "16.0" 33 "16.5" 34 "17.0" 35 "17.5" 36 "18.0" 37 "18.5" 38 "19.0" 39 "19.5" 40 "20.0" 41 "20.5" 42 "21.0" 43 "21.5" 44 "22.0" 45 "22.5" 46 "23.0" 47 "23.5" 48 "24.0" 49 "24.5" 50 "25.0" 51 "25.5" 52 "26.0" 53 "26.5" 54 "27.0" 55 "27.5" 56 "28.0" 57 "28.5" 58 "29.0" 59 "29.5" 60 "30.0" 61 "30.5" 62 "31.0" 63 "Invalid Value" 64 "Invalid Value" 65 "Invalid Value" 66 "Invalid Value" 67 "Invalid Value" 68 "Invalid Value" 69 "Invalid Value" 70 "Invalid Value" 71 "Invalid Value" 72 "Invalid Value" 73 "Invalid Value" 74 "Invalid Value" 75 "Invalid Value" 76 "Invalid Value" 77 "Invalid Value" 78 "Invalid Value" 79 "Invalid Value" 80 "Invalid Value" 81 "Invalid Value" 82 "Invalid Value" 83 "Invalid Value" 84 "Invalid Value" 85 "Invalid Value" 86 "Invalid Value" 87 "Invalid Value" 88 "Invalid Value" 89 "Invalid Value" 90 "Invalid Value" 91 "Invalid Value" 92 "Invalid Value" 93 "Invalid Value" 94 "Invalid Value" 95 "Invalid Value" 96 "Invalid Value" 97 "Invalid Value" 98 "Invalid Value" 99 "Invalid Value" 100 "Invalid Value" 101 "Invalid Value" 102 "Invalid Value" 103 "Invalid Value" 104 "Invalid Value" 105 "Invalid Value" 106 "Invalid Value" 107 "Invalid Value" 108 "Invalid Value" 109 "Invalid Value" 110 "Invalid Value" 111 "Invalid Value" 112 "Invalid Value" 113 "Invalid Value" 114 "Invalid Value" 115 "Invalid Value" 116 "Invalid Value" 117 "Invalid Value" 118 "Invalid Value" 119 "Invalid Value" 120 "Invalid Value" 121 "Invalid Value" 122 "Invalid Value" 123 "Invalid Value" 124 "Invalid Value" 125 "Invalid Value" 126 "Invalid Value" 127 "Invalid Value" 128 "Invalid Value" 129 "Invalid Value" 130 "Invalid Value" 131 "Invalid Value" 132 "Invalid Value" 133 "Invalid Value" 134 "Invalid Value" 135 "Invalid Value" 136 "Invalid Value" 137 "Invalid Value" 138 "Invalid Value" 139 "Invalid Value" 140 "Invalid Value" 141 "Invalid Value" 142 "Invalid Value" 143 "Invalid Value" 144 "Invalid Value" 145 "Invalid Value" 146 "Invalid Value" 147 "Invalid Value" 148 "Invalid Value" 149 "Invalid Value" 150 "Invalid Value" 151 "Invalid Value" 152 "Invalid Value" 153 "Invalid Value" 154 "Invalid Value" 155 "Invalid Value" 156 "Invalid Value" 157 "Invalid Value" 158 "Invalid Value" 159 "Invalid Value" 160 "Invalid Value" 161 "Invalid Value" 162 "Invalid Value" 163 "Invalid Value" 164 "Invalid Value" 165 "Invalid Value" 166 "Invalid Value" 167 "Invalid Value" 168 "Invalid Value" 169 "Invalid Value" 170 "Invalid Value" 171 "Invalid Value" 172 "Invalid Value" 173 "Invalid Value" 174 "Invalid Value" 175 "Invalid Value" 176 "Invalid Value" 177 "Invalid Value" 178 "Invalid Value" 179 "Invalid Value" 180 "Invalid Value" 181 "Invalid Value" 182 "Invalid Value" 183 "Invalid Value" 184 "Invalid Value" 185 "Invalid Value" 186 "Invalid Value" 187 "Invalid Value" 188 "Invalid Value" 189 "Invalid Value" 190 "Invalid Value" 191 "Invalid Value" 192 "Invalid Value" 193 "Invalid Value" 194 "Invalid Value" 195 "Invalid Value" 196 "Invalid Value" 197 "Invalid Value" 198 "Invalid Value" 199 "Invalid Value" 200 "Invalid Value" 201 "Invalid Value" 202 "Invalid Value" 203 "Invalid Value" 204 "Invalid Value" 205 "Invalid Value" 206 "Invalid Value" 207 "Invalid Value" 208 "Invalid Value" 209 "Invalid Value" 210 "Invalid Value" 211 "Invalid Value" 212 "Invalid Value" 213 "Invalid Value" 214 "Invalid Value" 215 "Invalid Value" 216 "Invalid Value" 217 "Invalid Value" 218 "Invalid Value" 219 "Invalid Value" 220 "Invalid Value" 221 "Invalid Value" 222 "Invalid Value" 223 "Invalid Value" 224 "Invalid Value" 225 "Invalid Value" 226 "Invalid Value" 227 "Invalid Value" 228 "Invalid Value" 229 "Invalid Value" 230 "Invalid Value" 231 "Invalid Value" 232 "Invalid Value" 233 "Invalid Value" 234 "Invalid Value" 235 "Invalid Value" 236 "Invalid Value" 237 "Invalid Value" 238 "Invalid Value" 239 "Invalid Value" 240 "Invalid Value" 241 "Invalid Value" 242 "Invalid Value" 243 "Invalid Value" 244 "Invalid Value" 245 "Invalid Value" 246 "Invalid Value" 247 "Invalid Value" 248 "Invalid Value" 249 "Invalid Value" 250 "Invalid Value" 251 "Invalid Value" 252 "Invalid Value" 253 "Invalid Value" 254 "Invalid Value" 255 "Invalid Value" ;
VAL_ 1849 Obstacle_Valid 1 "New valid " 2 "Older valid" ;
VAL_ 1849 Blinker_Info 0 "unavailable" 1 "Off" 2 "Left" 3 "Right" 4 "Both" ;
VAL_ 1849 Cut_in_and_out 0 "undefined " 1 "in_host_lane " 2 "out_host_lane " 3 "cut_in " 4 "cut_out " ;
VAL_ 1849 Obstacle_Brake_Lights 0 "object's brake lights are off" 1 "object's brake lights are on" ;
VAL_ 1849 Obstacle_Status 0 "Unused" 1 "Standing" 2 "Stopped " 3 "Moving" 4 "Oncoming" 5 "Parked " 6 "Unused" ;
VAL_ 1849 Obstacle_Type 0 "Vehicle" 1 "Truck" 2 "Bike" 3 "Ped" 4 "Bicycle" 5 "Unused" 6 "Unused" 7 "Unused" ;
VAL_ 1848 Failsafe 0 "No Failsafe" 1 "Low Sun" 2 "Blur Image" 3 "Unused" 4 "Unused" 5 "Unused" 6 "Unused" 7 "Unused" 8 "Unused" 9 "Unused" 10 "Unused" 11 "Unused" 12 "Unused" 13 "Unused" 14 "Unused" 15 "Unused" ;
VAL_ 1848 Close_car 0 "No close car" 1 "Close car exists" ;
VAL_ 1848 GO 0 "Stop" 1 "GO!" 2 "Undecided" 3 "Driver decision is required" 4 "unused" 5 "unused" 6 "unused" 7 "unused" 8 "unused" 9 "unused" 10 "unused" 11 "unused" 12 "unused" 13 "unused" 15 "Not Calculated " ;
VAL_ 1848 Right_close_rang_cut_in 0 "False" 1 "True" ;
VAL_ 1848 Left_close_rang_cut_in 0 "False" 1 "True" ;
VAL_ 1792 TSR_warning_level 0 "speed vehicle <= road speed+10" 1 "speed vehicle > road at speed" 2 "speed vehicle > road speed+5" 3 "speed vehicle > road speed+10" 4 "speed vehicle > road speed+15" 5 "speed vehicle > road speed+20" 6 "speed vehicle > road speed+25" 7 "speed vehicle > road speed+30" ;
VAL_ 1792 PCW_PedDZ 0 "No pedestrian" 2 "Pedestrian in danger zone" 3 "PCW" ;
VAL_ 1792 HW_Warning_level 0 "No CIPV in frame" 1 "CIPV >HW configuration " 2 "CIPV<= HW COFIGURATION" ;
VAL_ 1792 Blinker_reminder 0 "OFF" 1 "ON" ;
VAL_ 1792 FCW_on 0 "OFF" 1 "ON" ;
VAL_ 1792 LDW_off 0 "OFF" 1 "ON" ;
VAL_ 1792 Fail_safe 0 "OFF" 1 "ON" ;
VAL_ 1792 Headway_measurement 1 "HW=0.1" 2 "HW=0.2" 3 "HW=0.3" 4 "HW=0.4" 5 "HW=0.5" 6 "HW=0.6" 7 "HW=0.7" 8 "HW=0.8" 9 "HW=0.9" 10 "HW=1.0" 12 "HW=1.2" 14 "HW=1.4" 16 "HW=1.6" 18 "HW=1.8" 20 "HW=2.0" 25 "HW=2.5" ;
VAL_ 1792 Headway_valid 0 "OFF" 1 "ON" ;
VAL_ 1792 time_indicator 0 "Day" 1 "Dusk" 2 "Night" 3 "Not in use" ;
